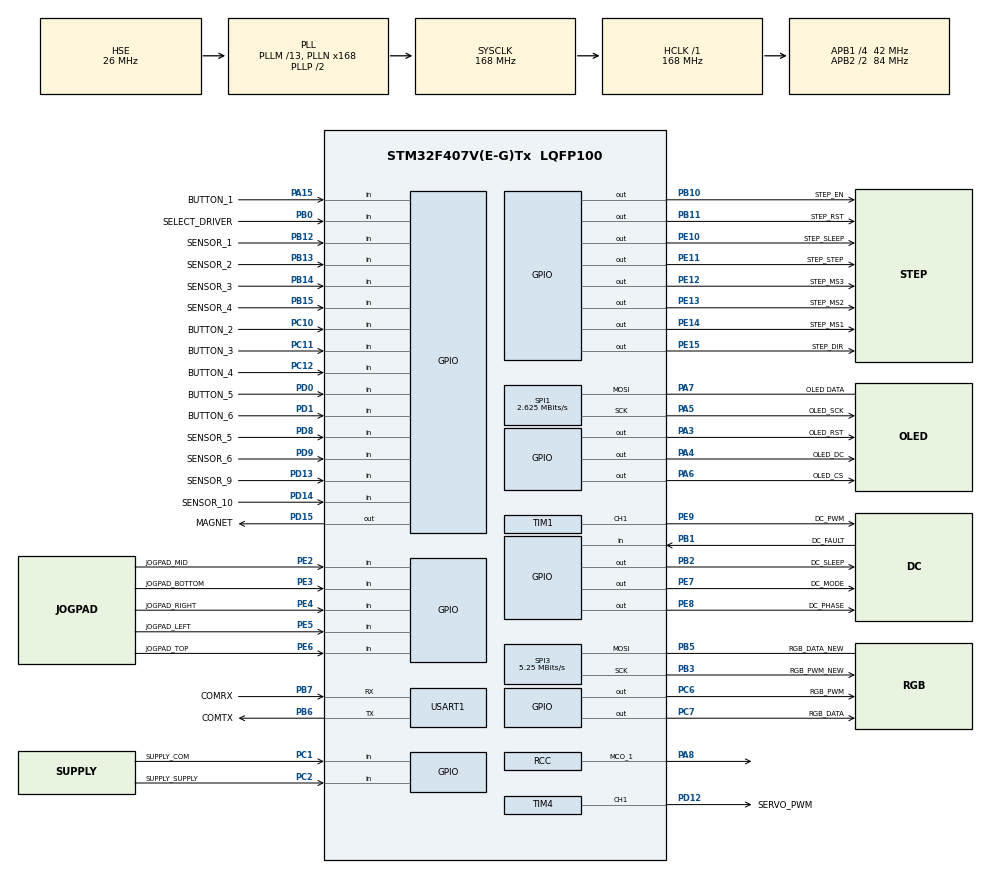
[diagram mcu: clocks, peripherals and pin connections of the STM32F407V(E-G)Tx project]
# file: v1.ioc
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Mcu.Family=STM32F4
Mcu.Name=STM32F407V(E-G)Tx
Mcu.Package=LQFP100
NVIC.PriorityGroup=NVIC_PRIORITYGROUP_4
NVIC.USART1_IRQn=true\:0\:0\:false\:true\:true\:1\:true\:true
PA13.Mode=Serial_Wire
PA13.Signal=SYS_JTMS-SWDIO
PA14.Mode=Serial_Wire
PA14.Signal=SYS_JTCK-SWCLK
PA15.GPIO_Label=BUTTON_1
PA15.GPIO_PuPd=GPIO_PULLDOWN
PA15.Signal=GPIO_Input
PA3.GPIO_Label=OLED_RST
PA3.GPIO_Speed=GPIO_SPEED_FREQ_MEDIUM
PA3.Signal=GPIO_Output
PA4.GPIO_Label=OLED_DC
PA4.GPIO_Speed=GPIO_SPEED_FREQ_MEDIUM
PA4.Signal=GPIO_Output
PA5.GPIO_Label=OLED_SCK
PA5.Mode=Simplex_Bidirectional_Master
PA5.Signal=SPI1_SCK
PA6.GPIO_Label=OLED_CS
PA6.GPIO_Speed=GPIO_SPEED_FREQ_MEDIUM
PA6.Signal=GPIO_Output
PA7.GPIO_Label=OLED DATA
PA7.Mode=Simplex_Bidirectional_Master
PA7.Signal=SPI1_MOSI
PA8.Mode=Clock-out-1
PA8.Signal=RCC_MCO_1
PB0.GPIO_Label=SELECT_DRIVER
PB0.GPIO_PuPd=GPIO_PULLDOWN
PB0.Signal=GPIO_Input
PB1.GPIO_Label=DC_FAULT
PB1.GPIO_PuPd=GPIO_PULLDOWN
PB1.Signal=GPIO_Input
PB10.GPIO_Label=STEP_EN
PB10.Signal=GPIO_Output
PB11.GPIO_Label=STEP_RST
PB11.Signal=GPIO_Output
PB12.GPIO_Label=SENSOR_1
PB12.GPIO_PuPd=GPIO_PULLDOWN
PB12.Signal=GPIO_Input
PB13.GPIO_Label=SENSOR_2
PB13.GPIO_PuPd=GPIO_PULLDOWN
PB13.Signal=GPIO_Input
PB14.GPIO_Label=SENSOR_3
PB14.GPIO_PuPd=GPIO_PULLDOWN
PB14.Signal=GPIO_Input
PB15.GPIO_Label=SENSOR_4
PB15.GPIO_PuPd=GPIO_PULLDOWN
PB15.Signal=GPIO_Input
PB2.GPIO_Label=DC_SLEEP
PB2.Signal=GPIO_Output
PB3.GPIO_Label=RGB_PWM_NEW
PB3.Mode=Simplex_Bidirectional_Master
PB3.Signal=SPI3_SCK
PB5.GPIO_Label=RGB_DATA_NEW
PB5.Mode=Simplex_Bidirectional_Master
PB5.Signal=SPI3_MOSI
PB6.GPIO_Label=COMTX
PB6.Mode=Asynchronous
PB6.Signal=USART1_TX
PB7.GPIO_Label=COMRX
PB7.Mode=Asynchronous
PB7.Signal=USART1_RX
PC1.GPIO_Label=SUPPLY_COM
PC1.GPIO_PuPd=GPIO_PULLDOWN
PC1.Signal=GPIO_Input
PC10.GPIO_Label=BUTTON_2
PC10.GPIO_PuPd=GPIO_PULLDOWN
PC10.Signal=GPIO_Input
PC11.GPIO_Label=BUTTON_3
PC11.GPIO_PuPd=GPIO_PULLDOWN
PC11.Signal=GPIO_Input
PC12.GPIO_Label=BUTTON_4
PC12.GPIO_PuPd=GPIO_PULLDOWN
PC12.Signal=GPIO_Input
PC2.GPIO_Label=SUPPLY_SUPPLY
PC2.GPIO_PuPd=GPIO_PULLDOWN
PC2.Signal=GPIO_Input
PC6.GPIO_Label=RGB_PWM
PC6.GPIO_Speed=GPIO_SPEED_FREQ_MEDIUM
PC6.PinState=GPIO_PIN_RESET
PC6.Signal=GPIO_Output
PC7.GPIO_Label=RGB_DATA
PC7.GPIO_Speed=GPIO_SPEED_FREQ_MEDIUM
PC7.Signal=GPIO_Output
PD0.GPIO_Label=BUTTON_5
PD0.GPIO_PuPd=GPIO_PULLDOWN
PD0.Signal=GPIO_Input
PD1.GPIO_Label=BUTTON_6
PD1.GPIO_PuPd=GPIO_PULLDOWN
PD1.Signal=GPIO_Input
PD12.GPIO_Label=SERVO_PWM
PD12.GPIO_Speed=GPIO_SPEED_FREQ_HIGH
PD12.Signal=S_TIM4_CH1
PD13.GPIO_Label=SENSOR_9
PD13.Signal=GPIO_Input
PD14.GPIO_Label=SENSOR_10
PD14.Signal=GPIO_Input
PD15.GPIO_Label=MAGNET
PD15.Signal=GPIO_Output
PD8.GPIO_Label=SENSOR_5
PD8.Signal=GPIO_Input
PD9.GPIO_Label=SENSOR_6
PD9.Signal=GPIO_Input
PE10.GPIO_Label=STEP_SLEEP
PE10.Signal=GPIO_Output
PE11.GPIO_Label=STEP_STEP
PE11.GPIO_Speed=GPIO_SPEED_FREQ_HIGH
PE11.Signal=GPIO_Output
PE12.GPIO_Label=STEP_MS3
PE12.GPIO_Speed=GPIO_SPEED_FREQ_LOW
PE12.Signal=GPIO_Output
PE13.GPIO_Label=STEP_MS2
PE13.Signal=GPIO_Output
PE14.GPIO_Label=STEP_MS1
PE14.Signal=GPIO_Output
PE15.GPIO_Label=STEP_DIR
PE15.Signal=GPIO_Output
PE2.GPIO_Label=JOGPAD_MID
PE2.GPIO_PuPd=GPIO_PULLDOWN
PE2.Signal=GPIO_Input
PE3.GPIO_Label=JOGPAD_BOTTOM
PE3.GPIO_PuPd=GPIO_PULLDOWN
PE3.Signal=GPIO_Input
PE4.GPIO_Label=JOGPAD_RIGHT
PE4.GPIO_PuPd=GPIO_PULLDOWN
PE4.Signal=GPIO_Input
PE5.GPIO_Label=JOGPAD_LEFT
PE5.GPIO_PuPd=GPIO_PULLDOWN
PE5.Signal=GPIO_Input
PE6.GPIO_Label=JOGPAD_TOP
PE6.GPIO_PuPd=GPIO_PULLDOWN
PE6.Signal=GPIO_Input
PE7.GPIO_Label=DC_MODE
PE7.Signal=GPIO_Output
PE8.GPIO_Label=DC_PHASE
PE8.Signal=GPIO_Output
PE9.GPIO_Label=DC_PWM
PE9.GPIO_Speed=GPIO_SPEED_FREQ_HIGH
PE9.Signal=S_TIM1_CH1
PH0-OSC_IN.Mode=HSE-External-Oscillator
PH0-OSC_IN.Signal=RCC_OSC_IN
PH1-OSC_OUT.Mode=HSE-External-Oscillator
PH1-OSC_OUT.Signal=RCC_OSC_OUT
ProjectManager.HeapSize=0x200
ProjectManager.StackSize=0x400
ProjectManager.TargetToolchain=MDK-ARM V5.27
RCC.48MHZClocksFreq_Value=48000000
RCC.AHBFreq_Value=168000000
RCC.APB1CLKDivider=RCC_HCLK_DIV4
RCC.APB1Freq_Value=42000000
RCC.APB1TimFreq_Value=84000000
RCC.APB2CLKDivider=RCC_HCLK_DIV2
RCC.APB2Freq_Value=84000000
RCC.APB2TimFreq_Value=168000000
RCC.CortexFreq_Value=168000000
RCC.HCLKFreq_Value=168000000
RCC.HSE_VALUE=26000000
RCC.HSI_VALUE=16000000
RCC.LSE_VALUE=32768
RCC.PLLM=13
RCC.PLLN=168
RCC.PLLQ=7
RCC.PLLSourceVirtual=RCC_PLLSOURCE_HSE
RCC.SYSCLKFreq_VALUE=168000000
RCC.SYSCLKSource=RCC_SYSCLKSOURCE_PLLCLK
RCC.VCOOutputFreq_Value=336000000
SH.S_TIM1_CH1.0=TIM1_CH1,PWM Generation1 CH1
SH.S_TIM4_CH1.0=TIM4_CH1,PWM Generation1 CH1
SPI1.BaudRatePrescaler=SPI_BAUDRATEPRESCALER_32
SPI1.CalculateBaudRate=2.625 MBits/s
SPI1.Direction=SPI_DIRECTION_1LINE
SPI1.Mode=SPI_MODE_MASTER
SPI1.VirtualType=VM_MASTER
SPI3.BaudRatePrescaler=SPI_BAUDRATEPRESCALER_8
SPI3.CalculateBaudRate=5.25 MBits/s
SPI3.Direction=SPI_DIRECTION_1LINE
SPI3.Mode=SPI_MODE_MASTER
SPI3.VirtualType=VM_MASTER
TIM1.Channel-PWM\ Generation1\ CH1=TIM_CHANNEL_1
TIM4.Channel-PWM\ Generation1\ CH1=TIM_CHANNEL_1
TIM4.Period=100
TIM4.Prescaler=84
USART1.VirtualMode=VM_ASYNC
VP_RNG_VS_RNG.Mode=RNG_Activate
VP_TIM4_VS_ClockSourceINT.Mode=Internal
board=custom

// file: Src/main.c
/* USER CODE BEGIN Header */
/**
  ******************************************************************************
  * @file           : main.c
  * @brief          : Main program body
  ******************************************************************************
  * @attention
  *
  * <h2><center>&copy; Copyright (c) 2020 STMicroelectronics.
  * All rights reserved.</center></h2>
  *
  * This software component is licensed by ST under BSD 3-Clause license,
  * the "License"; You may not use this file except in compliance with the
  * License. You may obtain a copy of the License at:
  *                        opensource.org/licenses/BSD-3-Clause
  *
  ******************************************************************************
  */
/* USER CODE END Header */
#include "main.h"

/* USER CODE BEGIN Includes */
#include "tlc5971.h"
/* USER CODE END Includes */

RNG_HandleTypeDef hrng;

SPI_HandleTypeDef hspi1;
SPI_HandleTypeDef hspi3;

TIM_HandleTypeDef htim1;
TIM_HandleTypeDef htim4;

UART_HandleTypeDef huart1;

void SystemClock_Config(void);
static void MX_GPIO_Init(void);
static void MX_RNG_Init(void);
static void MX_SPI1_Init(void);
static void MX_TIM1_Init(void);
static void MX_TIM4_Init(void);
static void MX_USART1_UART_Init(void);
static void MX_SPI3_Init(void);
static void MX_NVIC_Init(void);

int main(void)
{

  /* MCU Configuration--------------------------------------------------------*/

  /* Reset of all peripherals, Initializes the Flash interface and the Systick. */
  HAL_Init();

  /* Configure the system clock */
  SystemClock_Config();

  /* Initialize all configured peripherals */
  MX_GPIO_Init();
  MX_RNG_Init();
  MX_SPI1_Init();
  MX_TIM1_Init();
  MX_TIM4_Init();
  MX_USART1_UART_Init();
  MX_SPI3_Init();

  /* Initialize interrupts */
  MX_NVIC_Init();
  /* USER CODE BEGIN 2 */
	//magnet(1);
	RGB_setLED(1,30000,1000,5000);
  RGB_setLED(2,30000,1000,5000);
	RGB_setLED(3,30000,1000,5000);
	RGB_setLED(4,30000,1000,5000);
	RGB_setLED(5,30000,1000,5000);
	RGB_setLED(6,30000,1000,5000);
	RGB_setLED(7,30000,1000,5000);
	RGB_setLED(8,30000,1000,5000);

	RGB_setLED(7,0,0,0);
	RGB_setLED(8,0,0,0);
	/*RGB_setLED(2,1000,0,0);
	RGB_setLED(3,1000,0,0);
	RGB_setLED(4,1000,0,0);*/
	RGB_Setup();
	//HAL_GPIO_WritePin(RGB_PWM_GPIO_Port, RGB_PWM_Pin, GPIO_PIN_SET);
	//HAL_GPIO_WritePin(RGB_DATA_GPIO_Port, RGB_DATA_Pin, GPIO_PIN_SET);
	//GPIOC->BSRR = RGB_DATA_Pin;
	RGB_SHOW();
  /* USER CODE END 2 */

  /* Infinite loop */
  while (1)
  {

    /* USER CODE BEGIN 3 */
		//LEDC_CLKPuls();
  }
  /* USER CODE END 3 */
}

void SystemClock_Config(void)
{
  RCC_OscInitTypeDef RCC_OscInitStruct = {0};
  RCC_ClkInitTypeDef RCC_ClkInitStruct = {0};

  /** Configure the main internal regulator output voltage
  */
  __HAL_RCC_PWR_CLK_ENABLE();
  __HAL_PWR_VOLTAGESCALING_CONFIG(PWR_REGULATOR_VOLTAGE_SCALE1);
  /** Initializes the RCC Oscillators according to the specified parameters
  * in the RCC_OscInitTypeDef structure.
  */
  RCC_OscInitStruct.OscillatorType = RCC_OSCILLATORTYPE_HSI|RCC_OSCILLATORTYPE_HSE;
  RCC_OscInitStruct.HSEState = RCC_HSE_ON;
  RCC_OscInitStruct.HSIState = RCC_HSI_ON;
  RCC_OscInitStruct.HSICalibrationValue = RCC_HSICALIBRATION_DEFAULT;
  RCC_OscInitStruct.PLL.PLLState = RCC_PLL_ON;
  RCC_OscInitStruct.PLL.PLLSource = RCC_PLLSOURCE_HSE;
  RCC_OscInitStruct.PLL.PLLM = 13;
  RCC_OscInitStruct.PLL.PLLN = 168;
  RCC_OscInitStruct.PLL.PLLP = RCC_PLLP_DIV2;
  RCC_OscInitStruct.PLL.PLLQ = 7;
  if (HAL_RCC_OscConfig(&RCC_OscInitStruct) != HAL_OK)
  {
    Error_Handler();
  }
  /** Initializes the CPU, AHB and APB buses clocks
  */
  RCC_ClkInitStruct.ClockType = RCC_CLOCKTYPE_HCLK|RCC_CLOCKTYPE_SYSCLK
                              |RCC_CLOCKTYPE_PCLK1|RCC_CLOCKTYPE_PCLK2;
  RCC_ClkInitStruct.SYSCLKSource = RCC_SYSCLKSOURCE_PLLCLK;
  RCC_ClkInitStruct.AHBCLKDivider = RCC_SYSCLK_DIV1;
  RCC_ClkInitStruct.APB1CLKDivider = RCC_HCLK_DIV4;
  RCC_ClkInitStruct.APB2CLKDivider = RCC_HCLK_DIV2;

  if (HAL_RCC_ClockConfig(&RCC_ClkInitStruct, FLASH_LATENCY_5) != HAL_OK)
  {
    Error_Handler();
  }
  HAL_RCC_MCOConfig(RCC_MCO1, RCC_MCO1SOURCE_HSI, RCC_MCODIV_1);
}

/**
  * @brief NVIC Configuration.
  * @retval None
  */
static void MX_NVIC_Init(void)
{
  /* USART1_IRQn interrupt configuration */
  HAL_NVIC_SetPriority(USART1_IRQn, 0, 0);
  HAL_NVIC_EnableIRQ(USART1_IRQn);
}

static void MX_RNG_Init(void)
{

  hrng.Instance = RNG;
  if (HAL_RNG_Init(&hrng) != HAL_OK)
  {
    Error_Handler();
  }

}

static void MX_SPI1_Init(void)
{

  /* SPI1 parameter configuration*/
  hspi1.Instance = SPI1;
  hspi1.Init.Mode = SPI_MODE_MASTER;
  hspi1.Init.Direction = SPI_DIRECTION_1LINE;
  hspi1.Init.DataSize = SPI_DATASIZE_8BIT;
  hspi1.Init.CLKPolarity = SPI_POLARITY_LOW;
  hspi1.Init.CLKPhase = SPI_PHASE_1EDGE;
  hspi1.Init.NSS = SPI_NSS_SOFT;
  hspi1.Init.BaudRatePrescaler = SPI_BAUDRATEPRESCALER_32;
  hspi1.Init.FirstBit = SPI_FIRSTBIT_MSB;
  hspi1.Init.TIMode = SPI_TIMODE_DISABLE;
  hspi1.Init.CRCCalculation = SPI_CRCCALCULATION_DISABLE;
  hspi1.Init.CRCPolynomial = 10;
  if (HAL_SPI_Init(&hspi1) != HAL_OK)
  {
    Error_Handler();
  }

}

static void MX_SPI3_Init(void)
{

  /* SPI3 parameter configuration*/
  hspi3.Instance = SPI3;
  hspi3.Init.Mode = SPI_MODE_MASTER;
  hspi3.Init.Direction = SPI_DIRECTION_1LINE;
  hspi3.Init.DataSize = SPI_DATASIZE_8BIT;
  hspi3.Init.CLKPolarity = SPI_POLARITY_LOW;
  hspi3.Init.CLKPhase = SPI_PHASE_1EDGE;
  hspi3.Init.NSS = SPI_NSS_SOFT;
  hspi3.Init.BaudRatePrescaler = SPI_BAUDRATEPRESCALER_8;
  hspi3.Init.FirstBit = SPI_FIRSTBIT_MSB;
  hspi3.Init.TIMode = SPI_TIMODE_DISABLE;
  hspi3.Init.CRCCalculation = SPI_CRCCALCULATION_DISABLE;
  hspi3.Init.CRCPolynomial = 10;
  if (HAL_SPI_Init(&hspi3) != HAL_OK)
  {
    Error_Handler();
  }

}

static void MX_TIM1_Init(void)
{

  TIM_MasterConfigTypeDef sMasterConfig = {0};
  TIM_OC_InitTypeDef sConfigOC = {0};
  TIM_BreakDeadTimeConfigTypeDef sBreakDeadTimeConfig = {0};

  htim1.Instance = TIM1;
  htim1.Init.Prescaler = 0;
  htim1.Init.CounterMode = TIM_COUNTERMODE_UP;
  htim1.Init.Period = 65535;
  htim1.Init.ClockDivision = TIM_CLOCKDIVISION_DIV1;
  htim1.Init.RepetitionCounter = 0;
  htim1.Init.AutoReloadPreload = TIM_AUTORELOAD_PRELOAD_DISABLE;
  if (HAL_TIM_PWM_Init(&htim1) != HAL_OK)
  {
    Error_Handler();
  }
  sMasterConfig.MasterOutputTrigger = TIM_TRGO_RESET;
  sMasterConfig.MasterSlaveMode = TIM_MASTERSLAVEMODE_DISABLE;
  if (HAL_TIMEx_MasterConfigSynchronization(&htim1, &sMasterConfig) != HAL_OK)
  {
    Error_Handler();
  }
  sConfigOC.OCMode = TIM_OCMODE_PWM1;
  sConfigOC.Pulse = 0;
  sConfigOC.OCPolarity = TIM_OCPOLARITY_HIGH;
  sConfigOC.OCNPolarity = TIM_OCNPOLARITY_HIGH;
  sConfigOC.OCFastMode = TIM_OCFAST_DISABLE;
  sConfigOC.OCIdleState = TIM_OCIDLESTATE_RESET;
  sConfigOC.OCNIdleState = TIM_OCNIDLESTATE_RESET;
  if (HAL_TIM_PWM_ConfigChannel(&htim1, &sConfigOC, TIM_CHANNEL_1) != HAL_OK)
  {
    Error_Handler();
  }
  sBreakDeadTimeConfig.OffStateRunMode = TIM_OSSR_DISABLE;
  sBreakDeadTimeConfig.OffStateIDLEMode = TIM_OSSI_DISABLE;
  sBreakDeadTimeConfig.LockLevel = TIM_LOCKLEVEL_OFF;
  sBreakDeadTimeConfig.DeadTime = 0;
  sBreakDeadTimeConfig.BreakState = TIM_BREAK_DISABLE;
  sBreakDeadTimeConfig.BreakPolarity = TIM_BREAKPOLARITY_HIGH;
  sBreakDeadTimeConfig.AutomaticOutput = TIM_AUTOMATICOUTPUT_DISABLE;
  if (HAL_TIMEx_ConfigBreakDeadTime(&htim1, &sBreakDeadTimeConfig) != HAL_OK)
  {
    Error_Handler();
  }
  HAL_TIM_MspPostInit(&htim1);

}

static void MX_TIM4_Init(void)
{

  TIM_ClockConfigTypeDef sClockSourceConfig = {0};
  TIM_MasterConfigTypeDef sMasterConfig = {0};
  TIM_OC_InitTypeDef sConfigOC = {0};

  htim4.Instance = TIM4;
  htim4.Init.Prescaler = 84;
  htim4.Init.CounterMode = TIM_COUNTERMODE_UP;
  htim4.Init.Period = 100;
  htim4.Init.ClockDivision = TIM_CLOCKDIVISION_DIV1;
  htim4.Init.AutoReloadPreload = TIM_AUTORELOAD_PRELOAD_DISABLE;
  if (HAL_TIM_Base_Init(&htim4) != HAL_OK)
  {
    Error_Handler();
  }
  sClockSourceConfig.ClockSource = TIM_CLOCKSOURCE_INTERNAL;
  if (HAL_TIM_ConfigClockSource(&htim4, &sClockSourceConfig) != HAL_OK)
  {
    Error_Handler();
  }
  if (HAL_TIM_PWM_Init(&htim4) != HAL_OK)
  {
    Error_Handler();
  }
  sMasterConfig.MasterOutputTrigger = TIM_TRGO_RESET;
  sMasterConfig.MasterSlaveMode = TIM_MASTERSLAVEMODE_DISABLE;
  if (HAL_TIMEx_MasterConfigSynchronization(&htim4, &sMasterConfig) != HAL_OK)
  {
    Error_Handler();
  }
  sConfigOC.OCMode = TIM_OCMODE_PWM1;
  sConfigOC.Pulse = 0;
  sConfigOC.OCPolarity = TIM_OCPOLARITY_HIGH;
  sConfigOC.OCFastMode = TIM_OCFAST_DISABLE;
  if (HAL_TIM_PWM_ConfigChannel(&htim4, &sConfigOC, TIM_CHANNEL_1) != HAL_OK)
  {
    Error_Handler();
  }
  HAL_TIM_MspPostInit(&htim4);

}

static void MX_USART1_UART_Init(void)
{

  huart1.Instance = USART1;
  huart1.Init.BaudRate = 115200;
  huart1.Init.WordLength = UART_WORDLENGTH_8B;
  huart1.Init.StopBits = UART_STOPBITS_1;
  huart1.Init.Parity = UART_PARITY_NONE;
  huart1.Init.Mode = UART_MODE_TX_RX;
  huart1.Init.HwFlowCtl = UART_HWCONTROL_NONE;
  huart1.Init.OverSampling = UART_OVERSAMPLING_16;
  if (HAL_UART_Init(&huart1) != HAL_OK)
  {
    Error_Handler();
  }

}

static void MX_GPIO_Init(void)
{
  GPIO_InitTypeDef GPIO_InitStruct = {0};

  /* GPIO Ports Clock Enable */
  __HAL_RCC_GPIOE_CLK_ENABLE();
  __HAL_RCC_GPIOH_CLK_ENABLE();
  __HAL_RCC_GPIOC_CLK_ENABLE();
  __HAL_RCC_GPIOA_CLK_ENABLE();
  __HAL_RCC_GPIOB_CLK_ENABLE();
  __HAL_RCC_GPIOD_CLK_ENABLE();

  /*Configure GPIO pin Output Level */
  HAL_GPIO_WritePin(GPIOA, OLED_RST_Pin|OLED_DC_Pin|OLED_CS_Pin, GPIO_PIN_RESET);

  /*Configure GPIO pin Output Level */
  HAL_GPIO_WritePin(GPIOB, DC_SLEEP_Pin|STEP_EN_Pin|STEP_RST_Pin, GPIO_PIN_RESET);

  /*Configure GPIO pin Output Level */
  HAL_GPIO_WritePin(GPIOE, DC_MODE_Pin|DC_PHASE_Pin|STEP_SLEEP_Pin|STEP_STEP_Pin
                          |STEP_MS3_Pin|STEP_MS2_Pin|STEP_MS1_Pin|STEP_DIR_Pin, GPIO_PIN_RESET);

  /*Configure GPIO pin Output Level */
  HAL_GPIO_WritePin(MAGNET_GPIO_Port, MAGNET_Pin, GPIO_PIN_RESET);

  /*Configure GPIO pin Output Level */
  HAL_GPIO_WritePin(GPIOC, RGB_PWM_Pin|RGB_DATA_Pin, GPIO_PIN_RESET);

  /*Configure GPIO pins : JOGPAD_MID_Pin JOGPAD_BOTTOM_Pin JOGPAD_RIGHT_Pin JOGPAD_LEFT_Pin
                           JOGPAD_TOP_Pin */
  GPIO_InitStruct.Pin = JOGPAD_MID_Pin|JOGPAD_BOTTOM_Pin|JOGPAD_RIGHT_Pin|JOGPAD_LEFT_Pin
                          |JOGPAD_TOP_Pin;
  GPIO_InitStruct.Mode = GPIO_MODE_INPUT;
  GPIO_InitStruct.Pull = GPIO_PULLDOWN;
  HAL_GPIO_Init(GPIOE, &GPIO_InitStruct);

  /*Configure GPIO pins : SUPPLY_COM_Pin SUPPLY_SUPPLY_Pin BUTTON_2_Pin BUTTON_3_Pin
                           BUTTON_4_Pin */
  GPIO_InitStruct.Pin = SUPPLY_COM_Pin|SUPPLY_SUPPLY_Pin|BUTTON_2_Pin|BUTTON_3_Pin
                          |BUTTON_4_Pin;
  GPIO_InitStruct.Mode = GPIO_MODE_INPUT;
  GPIO_InitStruct.Pull = GPIO_PULLDOWN;
  HAL_GPIO_Init(GPIOC, &GPIO_InitStruct);

  /*Configure GPIO pins : OLED_RST_Pin OLED_DC_Pin OLED_CS_Pin */
  GPIO_InitStruct.Pin = OLED_RST_Pin|OLED_DC_Pin|OLED_CS_Pin;
  GPIO_InitStruct.Mode = GPIO_MODE_OUTPUT_PP;
  GPIO_InitStruct.Pull = GPIO_NOPULL;
  GPIO_InitStruct.Speed = GPIO_SPEED_FREQ_MEDIUM;
  HAL_GPIO_Init(GPIOA, &GPIO_InitStruct);

  /*Configure GPIO pins : SELECT_DRIVER_Pin DC_FAULT_Pin SENSOR_1_Pin SENSOR_2_Pin
                           SENSOR_3_Pin SENSOR_4_Pin */
  GPIO_InitStruct.Pin = SELECT_DRIVER_Pin|DC_FAULT_Pin|SENSOR_1_Pin|SENSOR_2_Pin
                          |SENSOR_3_Pin|SENSOR_4_Pin;
  GPIO_InitStruct.Mode = GPIO_MODE_INPUT;
  GPIO_InitStruct.Pull = GPIO_PULLDOWN;
  HAL_GPIO_Init(GPIOB, &GPIO_InitStruct);

  /*Configure GPIO pins : DC_SLEEP_Pin STEP_EN_Pin STEP_RST_Pin */
  GPIO_InitStruct.Pin = DC_SLEEP_Pin|STEP_EN_Pin|STEP_RST_Pin;
  GPIO_InitStruct.Mode = GPIO_MODE_OUTPUT_PP;
  GPIO_InitStruct.Pull = GPIO_NOPULL;
  GPIO_InitStruct.Speed = GPIO_SPEED_FREQ_LOW;
  HAL_GPIO_Init(GPIOB, &GPIO_InitStruct);

  /*Configure GPIO pins : DC_MODE_Pin DC_PHASE_Pin STEP_SLEEP_Pin STEP_MS3_Pin
                           STEP_MS2_Pin STEP_MS1_Pin STEP_DIR_Pin */
  GPIO_InitStruct.Pin = DC_MODE_Pin|DC_PHASE_Pin|STEP_SLEEP_Pin|STEP_MS3_Pin
                          |STEP_MS2_Pin|STEP_MS1_Pin|STEP_DIR_Pin;
  GPIO_InitStruct.Mode = GPIO_MODE_OUTPUT_PP;
  GPIO_InitStruct.Pull = GPIO_NOPULL;
  GPIO_InitStruct.Speed = GPIO_SPEED_FREQ_LOW;
  HAL_GPIO_Init(GPIOE, &GPIO_InitStruct);

  /*Configure GPIO pin : STEP_STEP_Pin */
  GPIO_InitStruct.Pin = STEP_STEP_Pin;
  GPIO_InitStruct.Mode = GPIO_MODE_OUTPUT_PP;
  GPIO_InitStruct.Pull = GPIO_NOPULL;
  GPIO_InitStruct.Speed = GPIO_SPEED_FREQ_HIGH;
  HAL_GPIO_Init(STEP_STEP_GPIO_Port, &GPIO_InitStruct);

  /*Configure GPIO pins : SENSOR_5_Pin SENSOR_6_Pin SENSOR_9_Pin SENSOR_10_Pin */
  GPIO_InitStruct.Pin = SENSOR_5_Pin|SENSOR_6_Pin|SENSOR_9_Pin|SENSOR_10_Pin;
  GPIO_InitStruct.Mode = GPIO_MODE_INPUT;
  GPIO_InitStruct.Pull = GPIO_NOPULL;
  HAL_GPIO_Init(GPIOD, &GPIO_InitStruct);

  /*Configure GPIO pin : MAGNET_Pin */
  GPIO_InitStruct.Pin = MAGNET_Pin;
  GPIO_InitStruct.Mode = GPIO_MODE_OUTPUT_PP;
  GPIO_InitStruct.Pull = GPIO_NOPULL;
  GPIO_InitStruct.Speed = GPIO_SPEED_FREQ_LOW;
  HAL_GPIO_Init(MAGNET_GPIO_Port, &GPIO_InitStruct);

  /*Configure GPIO pins : RGB_PWM_Pin RGB_DATA_Pin */
  GPIO_InitStruct.Pin = RGB_PWM_Pin|RGB_DATA_Pin;
  GPIO_InitStruct.Mode = GPIO_MODE_OUTPUT_PP;
  GPIO_InitStruct.Pull = GPIO_NOPULL;
  GPIO_InitStruct.Speed = GPIO_SPEED_FREQ_MEDIUM;
  HAL_GPIO_Init(GPIOC, &GPIO_InitStruct);

  /*Configure GPIO pin : PA8 */
  GPIO_InitStruct.Pin = GPIO_PIN_8;
  GPIO_InitStruct.Mode = GPIO_MODE_AF_PP;
  GPIO_InitStruct.Pull = GPIO_NOPULL;
  GPIO_InitStruct.Speed = GPIO_SPEED_FREQ_LOW;
  GPIO_InitStruct.Alternate = GPIO_AF0_MCO;
  HAL_GPIO_Init(GPIOA, &GPIO_InitStruct);

  /*Configure GPIO pin : BUTTON_1_Pin */
  GPIO_InitStruct.Pin = BUTTON_1_Pin;
  GPIO_InitStruct.Mode = GPIO_MODE_INPUT;
  GPIO_InitStruct.Pull = GPIO_PULLDOWN;
  HAL_GPIO_Init(BUTTON_1_GPIO_Port, &GPIO_InitStruct);

  /*Configure GPIO pins : BUTTON_5_Pin BUTTON_6_Pin */
  GPIO_InitStruct.Pin = BUTTON_5_Pin|BUTTON_6_Pin;
  GPIO_InitStruct.Mode = GPIO_MODE_INPUT;
  GPIO_InitStruct.Pull = GPIO_PULLDOWN;
  HAL_GPIO_Init(GPIOD, &GPIO_InitStruct);

}

void Error_Handler(void)
{
}

/************************ (C) COPYRIGHT STMicroelectronics *****END OF FILE****/
